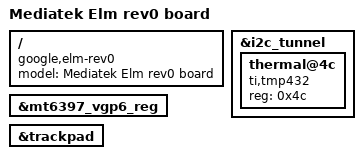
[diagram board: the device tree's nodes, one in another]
/*
 * Copyright 2016 MediaTek Inc.
 * Author: Eddie Huang <eddie.huang@mediatek.com>
 *
 * This program is free software; you can redistribute it and/or modify
 * it under the terms of the GNU General Public License version 2 as
 * published by the Free Software Foundation.
 *
 * This program is distributed in the hope that it will be useful,
 * but WITHOUT ANY WARRANTY; without even the implied warranty of
 * MERCHANTABILITY or FITNESS FOR A PARTICULAR PURPOSE.  See the
 * GNU General Public License for more details.
 */

/dts-v1/;
#include "mt8173-elm.dtsi"

/ {
	model = "Mediatek Elm rev0 board";
	compatible = "google,elm-rev0", "google,elm", "mediatek,mt8173";
};

&i2c_tunnel {
	thermal@4c {
		compatible = "ti,tmp432";
		reg = <0x4c>;
	};
};

&mt6397_vgp6_reg {
	/delete-property/regulator-always-on;
};

&trackpad {
	/delete-property/vcc-supply;
};
